AUTOSAR XML (schema 00044)
standard types defined: sint8, uint8
package /AtomicSwComponent
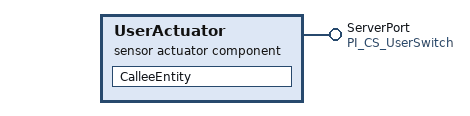
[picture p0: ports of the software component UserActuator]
  sensor actuator sw component type UserActuator
    provide port ServerPort: server-com-spec{operation=Operation, queue-length=1}, provided-interface=PI_CS_UserSwitch
    behavior UserActuator_IB: handle-termination-and-restart=NO-SUPPORT
      operation invoked event OI_CalleeEntity_ServerPort_Operation: start-on-event=CalleeEntity, operation=ServerPort.Operation
      runnable CalleeEntity: can-be-invoked-concurrently=true
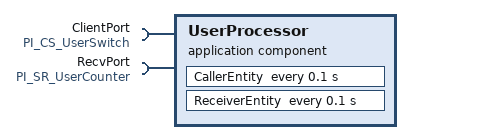
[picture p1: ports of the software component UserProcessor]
  application sw component type UserProcessor
    require port ClientPort: client-com-spec=Operation, required-interface=PI_CS_UserSwitch
    require port RecvPort: nonqueued-receiver-com-spec{data-element=DataElement, init-value=0}, required-interface=PI_SR_UserCounter
    behavior UserProcessor_IB: handle-termination-and-restart=NO-SUPPORT
      timing event T_100ms_CallerEntity: start-on-event=CallerEntity, period=0.1
      timing event T_100ms_ReceiverEntity: start-on-event=ReceiverEntity, period=0.1
      explicit-inter-runnable-variables:
        data localData: type=UserSwitch, init-value=0
      runnable CallerEntity
        read-local-variables:
          access RLV_localData: accessed-variable=localData
        sync call SSCP_ClientPort_Operation: operation=ClientPort.Operation, timeout=0.0
      runnable ReceiverEntity
        data-receive-point-by-arguments:
          access DRPA_RecvPort_DataElement: accessed-variable=RecvPort.DataElement
        read-local-variables:
          access WLV_localData: accessed-variable=localData
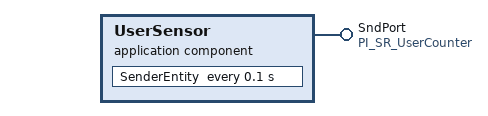
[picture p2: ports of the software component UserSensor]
  application sw component type UserSensor
    provide port SndPort: nonqueued-sender-com-spec{data-element=DataElement, init-value=0}, provided-interface=PI_SR_UserCounter
    behavior UserSensor_IB: handle-termination-and-restart=NO-SUPPORT
      timing event T_100ms_SenderEntity: start-on-event=SenderEntity, period=0.1
      runnable SenderEntity
        data-send-points:
          access DSP_SndPort_DataElement: accessed-variable=SndPort.DataElement
package /CompositionSwComponent
  composition sw component type LabEcu
    component UserActuator: type=UserActuator
    component UserProcessor: type=UserProcessor
    component UserSensor: type=UserSensor
    connect UserActuator.ServerPort -> UserProcessor.ClientPort
    connect UserSensor.SndPort -> UserProcessor.RecvPort
package /DataType/ApplicationDataType
  app type UserCounter: category=VALUE, range raw 0..9
  app type UserSwitch: category=VALUE, range raw 0..1
package /DataType/ImplementationDataType
  impl type UserCounter: category=VALUE, base-type=uint8
  impl type UserSwitch: category=VALUE, base-type=sint8
package /DataType/Mapping
  data type mapping set DataTypeMappingSet
    data-type-maps:
      application-data-type=UserCounter, implementation-data-type=UserCounter
      application-data-type=UserSwitch, implementation-data-type=UserSwitch
package /ECU
  ecu instance LabEcu: sleep-mode-supported=false, wake-up-over-bus-supported=false
package /PortInterface
  client server interface PI_CS_UserSwitch
    operation Operation
      arg Argument: type=UserSwitch, direction=IN
  sender receiver interface PI_SR_UserCounter
    data DataElement: type=UserCounter
package /SYSTEM
  system System: category=ECU_EXTRACT, system-version=1.0.0
    system mapping SystemMapping
      sw-mappings:
        swc to ecu mapping SwcToEcuMapping: component=[RootSwComposition.UserActuator, RootSwComposition.UserProcessor, RootSwComposition.UserSensor], ecu-instance=LabEcu
    root-software-compositions:
      root sw composition prototype RootSwComposition: software-composition=LabEcu
